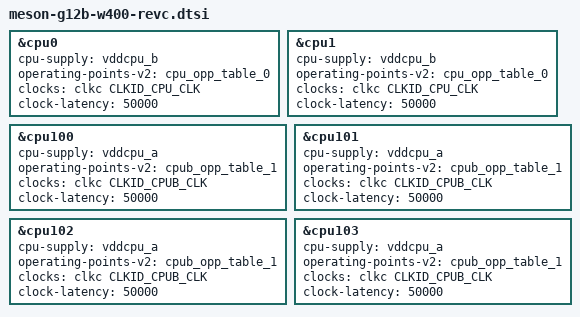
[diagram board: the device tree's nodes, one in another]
// SPDX-License-Identifier: (GPL-2.0+ OR MIT)
/*
 * Copyright (c) 2019 BayLibre, SAS
 * Author: Neil Armstrong <narmstrong@baylibre.com>
 * Copyright (c) 2019 Christian Hewitt <christianshewitt@gmail.com>
 */

#include "meson-g12b-w400.dtsi"
#include "meson-g12b-a311d.dtsi"

&cpu0 {
	cpu-supply = <&vddcpu_b>;
	operating-points-v2 = <&cpu_opp_table_0>;
	clocks = <&clkc CLKID_CPU_CLK>;
	clock-latency = <50000>;
};

&cpu1 {
	cpu-supply = <&vddcpu_b>;
	operating-points-v2 = <&cpu_opp_table_0>;
	clocks = <&clkc CLKID_CPU_CLK>;
	clock-latency = <50000>;
};

&cpu100 {
	cpu-supply = <&vddcpu_a>;
	operating-points-v2 = <&cpub_opp_table_1>;
	clocks = <&clkc CLKID_CPUB_CLK>;
	clock-latency = <50000>;
};

&cpu101 {
	cpu-supply = <&vddcpu_a>;
	operating-points-v2 = <&cpub_opp_table_1>;
	clocks = <&clkc CLKID_CPUB_CLK>;
	clock-latency = <50000>;
};

&cpu102 {
	cpu-supply = <&vddcpu_a>;
	operating-points-v2 = <&cpub_opp_table_1>;
	clocks = <&clkc CLKID_CPUB_CLK>;
	clock-latency = <50000>;
};

&cpu103 {
	cpu-supply = <&vddcpu_a>;
	operating-points-v2 = <&cpub_opp_table_1>;
	clocks = <&clkc CLKID_CPUB_CLK>;
	clock-latency = <50000>;
};
